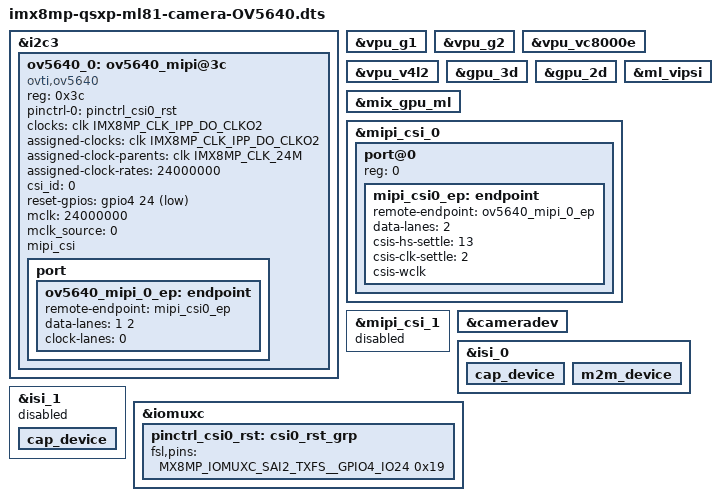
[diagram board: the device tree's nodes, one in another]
// SPDX-License-Identifier: (GPL-2.0 OR MIT)
/*
 * Copyright (C) 2021 Markus Bauer <mb@karo-electronics.de>
 *
 */

/dts-v1/;

#include "imx8mp-qsxp-ml81-camera.dts"

&i2c3 {
	ov5640_0: ov5640_mipi@3c {
		compatible = "ovti,ov5640";
		reg = <0x3c>;
		pinctrl-names = "default";
		pinctrl-0 = <&pinctrl_csi0_rst>;
		clocks = <&clk IMX8MP_CLK_IPP_DO_CLKO2>;
		clock-names = "xclk";
		assigned-clocks = <&clk IMX8MP_CLK_IPP_DO_CLKO2>;
		assigned-clock-parents = <&clk IMX8MP_CLK_24M>;
		assigned-clock-rates = <24000000>;
		csi_id = <0>;
		// powerdown-gpios = <&gpio4 1 GPIO_ACTIVE_HIGH>;
		reset-gpios = <&gpio4 24 (GPIO_ACTIVE_LOW | GPIO_OPEN_DRAIN)>;
		mclk = <24000000>;
		mclk_source = <0>;
		mipi_csi;
		status = "okay";

		port {
			ov5640_mipi_0_ep: endpoint {
				remote-endpoint = <&mipi_csi0_ep>;
				data-lanes = <1 2>;
				clock-lanes = <0>;
			};
		};
	};
};


&vpu_g1 {
	status = "okay";
};

&vpu_g2 {
	status = "okay";
};

&vpu_vc8000e {
	status = "okay";
};

&vpu_v4l2 {
	status = "okay";
};

&gpu_3d {
	status = "okay";
};

&gpu_2d {
	status = "okay";
};

&ml_vipsi {
	status = "okay";
};

&mix_gpu_ml {
	status = "okay";
};

&mipi_csi_0 {
	#address-cells = <1>;
	#size-cells = <0>;
	status = "okay";

	port@0 {
		reg = <0>;
		mipi_csi0_ep: endpoint {
			remote-endpoint = <&ov5640_mipi_0_ep>;
			data-lanes = <2>;
			csis-hs-settle = <13>;
			csis-clk-settle = <2>;
			csis-wclk;
		};
	};
};

&mipi_csi_1 {
	#address-cells = <1>;
	#size-cells = <0>;
	status = "disabled";

};

&cameradev {
	status = "okay";
};

&isi_0 {
	status = "okay";

	cap_device {
		status = "okay";
	};

	m2m_device {
		status = "okay";
	};
};

&isi_1 {
	status = "disabled";

	cap_device {
		status = "okay";
	};
};


&iomuxc {
	pinctrl_csi0_rst: csi0_rst_grp {
		fsl,pins = <
			MX8MP_IOMUXC_SAI2_TXFS__GPIO4_IO24		0x19
		>;
	};
};
